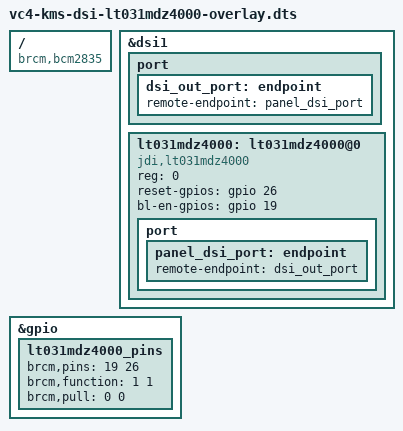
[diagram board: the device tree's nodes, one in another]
/dts-v1/;
/plugin/;

/ {
	compatible = "brcm,bcm2835";

	fragment@0 {
		target = <&dsi1>;
		__overlay__{
			status = "okay";
			#address-cells = <1>;
			#size-cells = <0>;
			port {
				dsi_out_port:endpoint {
					remote-endpoint = <&panel_dsi_port>;
				};
			};

			lt031mdz4000:lt031mdz4000@0 {
				compatible    = "jdi,lt031mdz4000";
				status        = "okay";
				reg           = <0>;
				reset-gpios   = <&gpio 26 0>;   // LCD RST
				bl-en-gpios  = <&gpio 19 0>;    // LCD backlight enable
				port {
					panel_dsi_port: endpoint {
						remote-endpoint = <&dsi_out_port>;
					};
				};
			};
		};
	};

	fragment@1 {
		target = <&gpio>;
		__overlay__ {
			lt031mdz4000_pins: lt031mdz4000_pins {
				brcm,pins = <19 26>;
				brcm,function = <1 1>; // out
				brcm,pull = <0 0>; // off
			};
		};

	};

	__overrides__ {
		reset = <&lt031mdz4000_pins>,"brcm,pins:8",
			<&lt031mdz4000>,"reset-gpios:4";

		bl-en = <&lt031mdz4000_pins>,"brcm,pins:0",
			<&lt031mdz4000>,"bl-en-gpios:4";

	};
};
